# BE-U1000 register map
Vendor: BAIKAL ELECTRONICS, JSC; File version: 1.0
CPU: RISC-V r0p0, little endian, no MPU, no FPU, 3 interrupt priority bits
Registers are 32-bit, read-write, reset 0x0 unless marked. A register's access mark holds for its fields unless they carry their own. Offsets are from the block's base; [hi:lo] are bit positions; {n}, {i} and the like mark numbered series; 'fields as' and 'values as' point back to an identical list.

## QSPI0 — Quad Serial Peripheral Interface
Base 0x11000000
Same registers: QSPI1 0x13000000
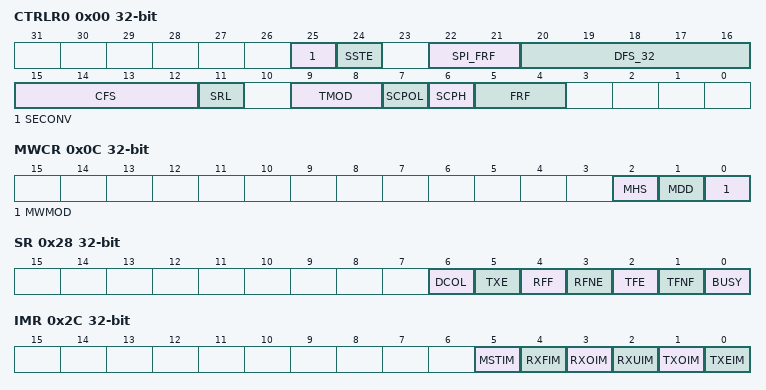
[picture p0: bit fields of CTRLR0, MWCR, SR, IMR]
0x00 CTRLR0 — Control 0
  [25] SECONV — Set the Endianness for XIP and data register reads
    0=DISABLED (fSAMPLING = fDTS/32, N = 8); 1=ENABLED (fSAMPLING = fDTS/32, N = 8)
  [24] SSTE — Slave Select Toggle Enable
    values as SECONV
  [22:21] SPI_FRF — SPI Frame Format
    0=STD (fSAMPLING = fDTS/32, N = 8); 1=DUAL (fSAMPLING = fDTS/32, N = 8); 2=QUAD (fSAMPLING = fDTS/32, N = 8)
  [20:16] DFS_32 — Data Frame Size
    {v}={v+1:02}_BIT (fSAMPLING = fDTS/32, N = 8) (v=3..31)
  [15:12] CFS — Control Frame Size
    {v}=fSAMPLING = fDTS/32, N = 8 (v=0..11); 13=fSAMPLING = fDTS/32, N = 8; 13=fSAMPLING = fDTS/32, N = 8; 14=fSAMPLING = fDTS/32, N = 8; 15=fSAMPLING = fDTS/32, N = 8
  [11] SRL — Shift Register Loop
    0=NORMAL (fSAMPLING = fDTS/32, N = 8); 1=TESTING (fSAMPLING = fDTS/32, N = 8)
  [9:8] TMOD — Transfer Mode
    0=TX_RX (fSAMPLING = fDTS/32, N = 8); 1=TX (fSAMPLING = fDTS/32, N = 8); 2=RX (fSAMPLING = fDTS/32, N = 8); 3=EEPROM_READ (fSAMPLING = fDTS/32, N = 8)
  [7] SCPOL — Serial Clock Polarity
    0=LOW (fSAMPLING = fDTS/32, N = 8); 1=HIGH (fSAMPLING = fDTS/32, N = 8)
  [6] SCPH — Serial Clock Phase
    0=MIDDLE (fSAMPLING = fDTS/32, N = 8); 1=START (fSAMPLING = fDTS/32, N = 8)
  [5:4] FRF — Frame Format
    0=SPI (fSAMPLING = fDTS/32, N = 8); 1=SSP (fSAMPLING = fDTS/32, N = 8); 2=MW (fSAMPLING = fDTS/32, N = 8)
0x04 CTRLR1 — Control 1
  [15:0] NDF — Number of Data Frames
0x08 QSPIENR — QSPI Enable
  [0] QSPI_EN
    values as CTRLR0.SECONV
0x0C MWCR — Microwire Control
  [2] MHS — Microwire Handshaking
    0=DISABLE (fSAMPLING = fDTS/32, N = 8); 1=ENABLE (fSAMPLING = fDTS/32, N = 8)
  [1] MDD — Microwire Control
    0=RECEIVE (fSAMPLING = fDTS/32, N = 8); 1=TRANSMIT (fSAMPLING = fDTS/32, N = 8)
  [0] MWMOD — Microwire Transfer Mode
    0=NON_SEQUENTIAL (fSAMPLING = fDTS/32, N = 8); 1=SEQUENTIAL (fSAMPLING = fDTS/32, N = 8)
0x10 SER — Slave Enable
  [2:0] SER — Slave Select Enable Flag
    0=NOT_SELECTED (fSAMPLING = fDTS/32, N = 8); 1=fSAMPLING = fDTS/32, N = 8; 2=fSAMPLING = fDTS/32, N = 8; 4=fSAMPLING = fDTS/32, N = 8
0x14 BAUDR — Baud Rate Select
  [15:0] SCKDV — SSI Clock Divider
0x18 TXFTLR — Transmit FIFO Threshold Level
  [2:0] TFT — Transmit FIFO Threshold
0x1C RXFTLR — Receive FIFO Threshold Level
  [2:0] RFT — Receive FIFO Threshold
0x20 TXFLR — Transmit FIFO Level
  [2:0] TXTFL
0x24 RXFLR — Receive FIFO Level
  [2:0] RXTFL
0x28 SR — Status
  [6] DCOL — Data Collision Error
    0=NO_ERROR_CONDITION (fSAMPLING = fDTS/32, N = 8); 1=TX_COLLISION_ERROR (fSAMPLING = fDTS/32, N = 8)
  [5] TXE — Transmission Error
    0=NO_ERROR (fSAMPLING = fDTS/32, N = 8); 1=TX_ERROR (fSAMPLING = fDTS/32, N = 8)
  [4] RFF — Receive FIFO Full
    0=NOT_FULL (fSAMPLING = fDTS/32, N = 8); 1=FULL (fSAMPLING = fDTS/32, N = 8)
  [3] RFNE — Receive FIFO Not Empty
    0=EMPTY (fSAMPLING = fDTS/32, N = 8); 1=NOT_EMPTY (fSAMPLING = fDTS/32, N = 8)
  [2] TFE — Transmit FIFO Empty
    0=NOT_EMPTY (fSAMPLING = fDTS/32, N = 8); 1=EMPTY (fSAMPLING = fDTS/32, N = 8)
  [1] TFNF — Transmit FIFO Not Full
    0=FULL (fSAMPLING = fDTS/32, N = 8); 1=NON_FULL (fSAMPLING = fDTS/32, N = 8)
  [0] BUSY — QSPI Busy Flag
    0=INACTIVE (fSAMPLING = fDTS/32, N = 8); 1=ACTIVE (fSAMPLING = fDTS/32, N = 8)
0x2C IMR — Interrupt Mask
  [all] fields
    0=MASKED (fSAMPLING = fDTS/32, N = 8); 1=UNMASKED (fSAMPLING = fDTS/32, N = 8)
  [5] MSTIM — Multi-Master Contention Interrupt Mask
  [4] RXFIM — Receive FIFO Full Interrupt Mask
  [3] RXOIM — Receive FIFO Overflow Interrupt Mask
  [2] RXUIM — Receive FIFO Underflow Interrupt Mask
  [1] TXOIM — Transmit FIFO Overflow Interrupt Mask
  [0] TXEIM — Transmit FIFO Empty Interrupt Mask
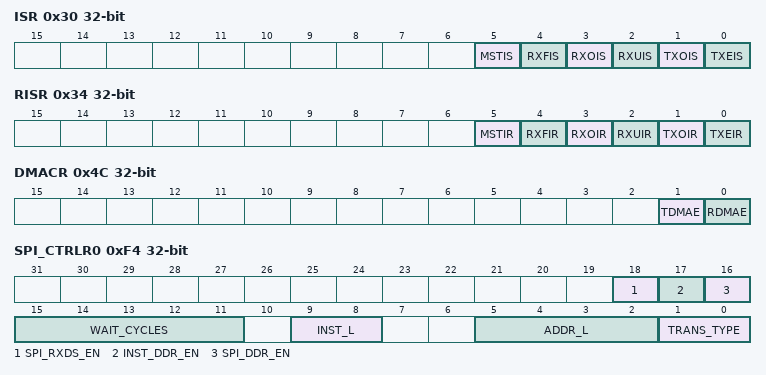
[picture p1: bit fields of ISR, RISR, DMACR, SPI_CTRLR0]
0x30 ISR — Interrupt Status
  [all] fields
    values as SR.BUSY
  [5] MSTIS — Multi-Master Contention Interrupt Status
  [4] RXFIS — Receive FIFO Full Interrupt Status
  [3] RXOIS — Receive FIFO Overflow Interrupt Status
  [2] RXUIS — Receive FIFO Underflow Interrupt Status
  [1] TXOIS — Transmit FIFO Overflow Interrupt Status
  [0] TXEIS — Transmit FIFO Empty Interrupt Status
0x34 RISR — Raw Interrupt Status
  [all] fields
    values as SR.BUSY
  [5] MSTIR — Multi-Master Contention Raw Interrupt Status
  [4] RXFIR — Receive FIFO Full Raw Interrupt Status
  [3] RXOIR — Receive FIFO Overflow Raw Interrupt Status
  [2] RXUIR — Receive FIFO Underflow Raw Interrupt Status
  [1] TXOIR — Transmit FIFO Overflow Raw Interrupt Status
  [0] TXEIR — Transmit FIFO Empty Raw Interrupt Status
0x38 TXOICR — Transmit FIFO Overflow Interrupt Clear
  [0] TXOICR — Clear Transmit FIFO Overflow Interrupt
    0=DISABLE; 1=ENABLE
0x3C RXOICR — Receive FIFO Overflow Interrupt Clear
  [0] RXOICR — Clear Receive FIFO Overflow Interrupt
    0=DISABLE; 1=ENABLE
0x40 RXUICR — Receive FIFO Underflow Interrupt Clear
  [0] RXUICR — Clear Receive FIFO Underflow Interrupt
    0=DISABLE; 1=ENABLE
0x44 MSTICR — Multi-Master Interrupt Clear
  [0] MSTICR — Clear Multi-Master Contention Interrupt
    0=DISABLE; 1=ENABLE
0x48 ICR — Interrupt Clear
  [0] ICR — Clear Interrupts
    0=DISABLE; 1=ENABLE
0x4C DMACR — DMA Control
  [1] TDMAE — Transmit DMA Enable
    values as MWCR.MHS
  [0] RDMAE — Receive DMA Enable
    values as MWCR.MHS
0x50 DMATDLR — DMA Transmit Data Level
  [2:0] DMATDL — Transmit Data Level
0x54 DMARDLR — DMA Receive Data Level
  [2:0] DMARDL — Receive Data Level
0x58 IDR — Identification
  [31:0] IDCODE — Identification code
0x5C VER_ID — Version ID
  [31:0] COMP_VER — Hex representation of component version
{0x60+4i} DR[{i}] (i=0..35) — Data x
  [31:0] DR — Data Register
0xF0 RX_SAMPLE_DLY — RX Sample Delay
  [7:0] RSD — Rxd Sample Delay
0xF4 SPI_CTRLR0 — SPI Control
  [18] SPI_RXDS_EN — Read data strobe enable bit
    0=DISABLE; 1=ENABLE
  [17] INST_DDR_EN — Instruction DDR Enable bit
    values as MWCR.MHS
  [16] SPI_DDR_EN — SPI DDR Enable bit
    values as MWCR.MHS
  [15:11] WAIT_CYCLES
    {v}=fSAMPLING = fDTS/32, N = 8 (v=0..31)
  [9:8] INST_L — Instruction Length
    {v}=fSAMPLING = fDTS/32, N = 8 (v=0..3)
  [5:2] ADDR_L — Address Length
    {v}=fSAMPLING = fDTS/32, N = 8 (v=0..15)
  [1:0] TRANS_TYPE — Address and instruction transfer format
    0=STD (fSAMPLING = fDTS/32, N = 8); 1=INST (fSAMPLING = fDTS/32, N = 8); 2=BOTH (fSAMPLING = fDTS/32, N = 8)
0xF8 TXD_DRIVE_EDGE — Transmit Drive Edge
  [7:0] TDE — TXD Drive edge

## SPI0 — Serial Peripheral Interface (SPI)
Base 0x1100B000
Same registers: SPI1 0x1100C000, SPI2 0x1300B000, SPI3 0x1300C000
Registers as QSPI0, without QSPIENR, VER_ID, SPI_CTRLR0; these are added or differ:
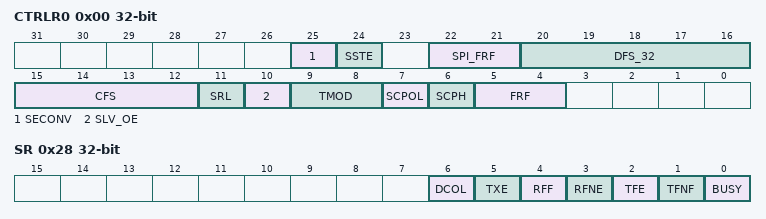
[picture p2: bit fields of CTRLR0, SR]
0x00 CTRLR0 — Control 0
  [25] SECONV — Set the Endianness for data register reads
    0=DISABLED (fSAMPLING = fDTS/32, N = 8); 1=ENABLED (fSAMPLING = fDTS/32, N = 8)
  [24] SSTE — Slave Select Toggle Enable
    values as SECONV
  [22:21] SPI_FRF — SPI Frame Format
    0=STD (fSAMPLING = fDTS/32, N = 8); 1=DUAL (fSAMPLING = fDTS/32, N = 8); 2=QUAD (fSAMPLING = fDTS/32, N = 8); 3=OCTAL (fSAMPLING = fDTS/32, N = 8)
  [20:16] DFS_32 — Data Frame Size
    {v}={v+1:02}_BIT (fSAMPLING = fDTS/32, N = 8) (v=3..31)
  [15:12] CFS — Control Frame Size for Microwire frame format
    {v}={v+1:02}_BIT (fSAMPLING = fDTS/32, N = 8) (v=0..15)
  [11] SRL — Shift Register Loop
    0=NORMAL (fSAMPLING = fDTS/32, N = 8); 1=TESTING (fSAMPLING = fDTS/32, N = 8)
  [10] SLV_OE — Slave Output Enable
    values as SECONV
  [9:8] TMOD — Transfer Mode
    0=TX_RX (fSAMPLING = fDTS/32, N = 8); 1=TX (fSAMPLING = fDTS/32, N = 8); 2=RX (fSAMPLING = fDTS/32, N = 8); 3=EEPROM_READ (fSAMPLING = fDTS/32, N = 8)
  [7] SCPOL — Serial Clock Polarity
    0=LOW (fSAMPLING = fDTS/32, N = 8); 1=HIGH (fSAMPLING = fDTS/32, N = 8)
  [6] SCPH — Serial Clock Phase
    0=MIDDLE (fSAMPLING = fDTS/32, N = 8); 1=START (fSAMPLING = fDTS/32, N = 8)
  [5:4] FRF — Frame Format
    0=SPI (fSAMPLING = fDTS/32, N = 8); 1=SSP (fSAMPLING = fDTS/32, N = 8); 2=MW (fSAMPLING = fDTS/32, N = 8)
0x08 SPIENR — SPI Enable
  [0] SPI_EN
    values as CTRLR0.SECONV
0x10 SER — Slave Enable
  [2:0] SER — Slave Select Enable Flag
    0=NOT_SELECTED (fSAMPLING = fDTS/32, N = 8); 1=SELECTED (fSAMPLING = fDTS/32, N = 8)
0x18 TXFTLR — Transmit FIFO Threshold Level
  [5:0] TFT — Transmit FIFO Threshold
0x20 TXFLR — Transmit FIFO Level
  [5:0] TXTFL
0x28 SR — Status
  [6] DCOL — Data Collision Error
    0=NO_ERROR_CONDITION (fSAMPLING = fDTS/32, N = 8); 1=TX_COLLISION_ERROR (fSAMPLING = fDTS/32, N = 8)
  [5] TXE — Transmission Error
    0=NO_ERROR (fSAMPLING = fDTS/32, N = 8); 1=TX_ERROR (fSAMPLING = fDTS/32, N = 8)
  [4] RFF — Receive FIFO Full
    0=NOT_FULL (fSAMPLING = fDTS/32, N = 8); 1=FULL (fSAMPLING = fDTS/32, N = 8)
  [3] RFNE — Receive FIFO Not Empty
    0=EMPTY (fSAMPLING = fDTS/32, N = 8); 1=NOT_EMPTY (fSAMPLING = fDTS/32, N = 8)
  [2] TFE — Transmit FIFO Empty
    0=NOT_EMPTY (fSAMPLING = fDTS/32, N = 8); 1=EMPTY (fSAMPLING = fDTS/32, N = 8)
  [1] TFNF — Transmit FIFO Not Full
    0=FULL (fSAMPLING = fDTS/32, N = 8); 1=NON_FULL (fSAMPLING = fDTS/32, N = 8)
  [0] BUSY — SPI Busy Flag
    0=INACTIVE (fSAMPLING = fDTS/32, N = 8); 1=ACTIVE (fSAMPLING = fDTS/32, N = 8)
0x50 DMATDLR — DMA Transmit Data Level
  [5:0] DMATDL — Transmit Data Level
0x5C VERSION_ID
  [31:0] COMP_VERSION — Hex representation of component version
